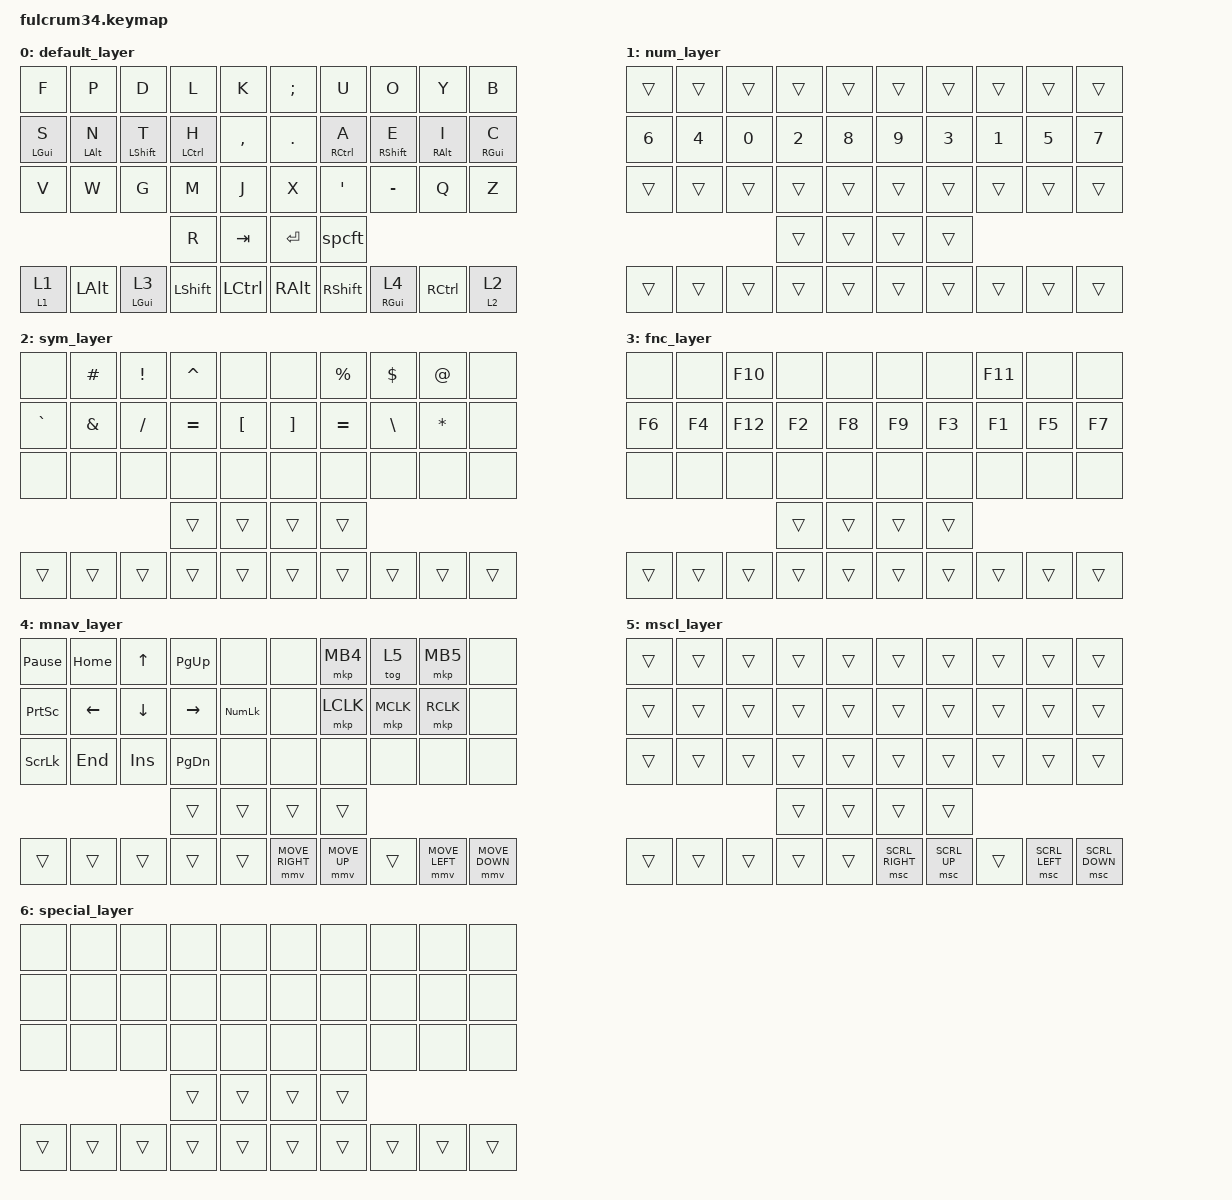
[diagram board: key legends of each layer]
/*
 * Copyright (c) 2020 The ZMK Contributors
 *
 * SPDX-License-Identifier: MIT
 */

#include <behaviors.dtsi>
#include <dt-bindings/zmk/keys.h>
#include <dt-bindings/zmk/bt.h>
#include <dt-bindings/zmk/outputs.h>
#include <dt-bindings/zmk/ext_power.h>
#include <dt-bindings/zmk/pointing.h>

#define DEFAULT 0
#define NUM 1
#define SYM 2
#define FNC 3
#define MNAV 4
#define MSCL 5
#define SPECIAL 6

/ {
    behaviors {
        hml: balanced_homerow_mods_left {
            compatible = "zmk,behavior-hold-tap";
            #binding-cells = <2>;
            tapping-term-ms = <200>;
            quick-tap-ms = <0>;
			require-prior-idle-ms = <20>;
            hold-trigger-key-positions = <5 6 7 8 9>, <15 16 17 18 19>, <25 26 27 28 29>, <30 31 32 33>, <34 35 36 37 38 39 40 41 42 43>;
			hold-trigger-on-release;
            flavor = "balanced";
            bindings = <&kp>, <&kp>;
        };
        hmr: balanced_homerow_mods_right {
            compatible = "zmk,behavior-hold-tap";
            #binding-cells = <2>;
            tapping-term-ms = <200>;
            quick-tap-ms = <0>;
			require-prior-idle-ms = <20>;
            hold-trigger-key-positions = <0 1 2 3 4>, <10 11 12 13 14>, <20 21 22 23 24>, <30 31 32 33>, <34 35 36 37 38 39 40 41 42 43>;
			hold-trigger-on-release;
            flavor = "balanced";
            bindings = <&kp>, <&kp>;
        };
		mo_tog: behavior_mo_tog {
            compatible = "zmk,behavior-hold-tap";
            #binding-cells = <2>;
            flavor = "hold-preferred";
            tapping-term-ms = <200>;
            bindings = <&mo>, <&tog>;
        };
        h_tog: behavior_hold_toggle_layer {
            compatible = "zmk,behavior-hold-tap";
            #binding-cells = <2>;
            tapping-term-ms = <200>;
            quick-tap-ms = <0>;
			require-prior-idle-ms = <20>;
            flavor = "hold-preferred";
            bindings = <&kp>, <&tog>;
        };
        h_sl: behavior_hold_sticky_layer {
            compatible = "zmk,behavior-hold-tap";
            #binding-cells = <2>;
            tapping-term-ms = <200>;
            quick-tap-ms = <0>;
			require-prior-idle-ms = <20>;
            flavor = "hold-preferred";
            bindings = <&kp>, <&sl>;
        };
		spcft: holdtap_space_faux_tab {
			compatible = "zmk,behavior-hold-tap";
			#binding-cells = <2>;
			tapping-term-ms = <200>;
			quick-tap-ms = <0>;
			require-prior-idle-ms = <20>;
			flavor = "balanced";
			bindings = <&fauxt>, <&kp SPACE>;
		};
		caps: holdtap_capsword {
			compatible = "zmk,behavior-hold-tap";
			#binding-cells = <2>;
			tapping-term-ms = <200>;
			quick-tap-ms = <0>;
			require-prior-idle-ms = <20>;
			flavor = "balanced";
			bindings = <&kp CAPS>, <&caps_word>;
		};
		caps_word: caps_word {
			compatible = "zmk,behavior-caps-word";
			#binding-cells = <0>;
			continue-list = <UNDERSCORE MINUS>;
		};
        tdbl: tap_dance_bootloader {
            compatible = "zmk,behavior-tap-dance";
            #binding-cells = <0>;
            tapping-term-ms = <200>;
            bindings = <&kp>, <&kp>, <&bootloader>;
        };
    };
	
    combos {
        compatible = "zmk,combos";
		combo_lthumb_bspc {
		    key-positions = <30 31>;
			bindings = <&kp BSPC>;
		};
		combo_rthumb_del {
		    key-positions = <32 33>;
			bindings = <&kp DEL>;
		};
		combo_ldwrdw_special_layer {
            key-positions = <34 43>;
            bindings = <&mo 6>;
        };
		combo_luprup_caps {
            key-positions = <37 40>;
            bindings = <&caps>;
        };
		combo_lfwrfw_app {
            key-positions = <38 42>;
            bindings = <&kp KP_APP>;
        };
		combo_lbkrbk_ {
            key-positions = <35 39>;
            bindings = <&kp>;
        };
		combo_linrin_ {
            key-positions = <36 41>;
            bindings = <&kp>;
        };
    };
	
	macros {
		fauxt: faux_tab {
          compatible = "zmk,behavior-macro";
          #binding-cells = <0>;
          bindings = <&macro_tap &kp SPACE &kp SPACE &kp SPACE &kp SPACE>;
      };
	};
	
        keymap {
                compatible = "zmk,keymap";
                default_layer {
// -------------------------------------------------------------------------------
// |   F  |   P  |   D  |   L  |   K  ||     ||   ;: |   U  |   O  |   Y  |   B  |
// |gui S |alt N |sft T |ctl H |   ,< |||||||||   .> |ctl A |sft E |alt I |gui C |
// |   V  |   W  |   G  |   M  |   J  ||     ||   X  |   '" |   -_ |   Q  |   Z  |
// _____________________|   R  |  tab ||     ||  ret | spcft|_____________________
// |  L1  |  alt |  gui | shft | ctrl ||     ||  alt | shft |  gui | ctrl |  L2  |
// (  DW  |  BK  |  IN  |  UP  |  FW  )       (  BK  |  UP  |  IN  |  FW  |  DW  )
                        bindings = <
   &kp F &kp P &kp D &kp L &kp K   &kp SEMI &kp U &kp O &kp Y &kp B    
   &hml LGUI S &hml LALT N &hml LSHFT T &hml LCTRL H &kp COMMA   &kp DOT &hmr RCTRL A &hmr RSHFT E &hmr RALT I &hmr RGUI C  
   &kp V &kp W &kp G &kp M &kp J   &kp X &kp QUOT &kp MINUS &kp Q &kp Z
                     &kp R &kp TAB  &kp RET &spcft
   &mo_tog 1 1 &kp LALT &h_sl LGUI 3 &kp LSHFT &kp LCTRL    &kp RALT &kp RSHFT &h_tog RGUI 4 &kp RCTRL &mo_tog 2 2
                        >;
                };
              num_layer {
// -------------------------------------------------------------------------------
// |      |      |      |      |      ||     ||      |      |      |      |      |
// |   6  |   4  |   0  |   2  |   8  |||||||||   9  |   3  |   1  |   5  |   7  |
// |      |      |      |      |      ||     ||      |      |      |      |      |
// _____________________|      |      ||     ||      |      |_____________________
// |      |      |      |      |      ||     ||      |      |      |      |      |
// (  DW  |  BK  |  IN  |  UP  |  FW  )       (  BK  |  UP  |  IN  |  FW  |  DW  )
                      bindings = <
 &trans &trans &trans &trans &trans   &trans &trans &trans &trans &trans
 &kp N6 &kp N4 &kp N0 &kp N2 &kp N8   &kp N9 &kp N3 &kp N1 &kp N5 &kp N7
 &trans &trans &trans &trans &trans   &trans &trans &trans &trans &trans
                   &trans &trans   &trans &trans
 &trans &trans &trans &trans &trans    &trans &trans &trans &trans &trans
                      >;
              };
                sym_layer {
// -------------------------------------------------------------------------------
// |      |   #  |   !  |   ^  |      ||     ||      |   %  |   $  |   @  |      |
// |  `~  |   &  |  /?  |  =+  |  [{  |||||||||  }]  |  =+  |  \|  |   *  |      |
// |      |      |      |      |      ||     ||      |      |      |      |      |
// _____________________|      |      ||     ||      |      |_____________________
// |      |      |      |      |      ||     ||      |      |      |      |      |
// (  DW  |  BK  |  IN  |  UP  |  FW  )       (  BK  |  UP  |  IN  |  FW  |  DW  )
                        bindings = <
   &none &kp HASH &kp EXCL &kp CARET &none   &none &kp PRCNT &kp DLLR &kp AT &none
   &kp GRAVE &kp AMPS &kp FSLH &kp EQUAL &kp LBKT   &kp RBKT &kp EQUAL &kp BSLH &kp ASTRK &none
   &none &none &none &none &none   &none &none &none &none &none
                     &trans &trans   &trans &trans
   &trans &trans &trans &trans &trans    &trans &trans &trans &trans &trans 
                        >;
                };
//              sym_layer { // BAK
// -------------------------------------------------------------------------------
// |   ~  |   @  |   <  |   {  |   [  ||     ||   ]  |   }  |   >  |   @  |   ~  |
// |   ^  |   +  |   *  |   &  |   =  |||||||||   =  |   &  |   *  |   +  |   ^  |
// |   `  |   %  |   $  |   |  |   #  ||     ||   #  |   |  |   $  |   %  |   `  |
// _____________________|      |      ||     ||      |      |_____________________
// |      |      |      |      |      ||     ||      |      |      |      |      |
// (  DW  |  BK  |  IN  |  UP  |  FW  )       (  BK  |  UP  |  IN  |  FW  |  DW  )
//                      bindings = <
// &kp TILDE &kp AT &kp LT &kp LBRC &kp LBKT   &kp RBKT &kp RBRC &kp GT &kp AT &kp TILDE
// &kp CARET &kp PLUS &kp STAR &kp AMPS &kp EQUAL   &kp EQUAL &kp AMPS &kp STAR &kp PLUS &kp CARET
// &kp GRAVE &kp PRCNT &kp DLLR &kp PIPE &kp HASH   &kp HASH &kp PIPE &kp DLLR &kp PRCNT &kp GRAVE
//                   &trans &trans   &trans &trans
// &trans &trans &trans &trans &trans    &trans &trans &trans &trans &trans
//                      >;
//              };
                fnc_layer {
// -------------------------------------------------------------------------------
// |      |      |  F10 |      |      ||     ||      |      |  F11 |      |      |
// |  F6  |  F4  |  F12 |  F2  |  F8  |||||||||  F9  |  F3  |  F1  |  F5  |  F7  |
// |      |      |      |      |      ||     ||      |      |      |      |      |
// _____________________|      |      ||     ||      |      |_____________________
// |      |      |      |      |      ||     ||      |      |      |      |      |
// (  DW  |  BK  |  IN  |  UP  |  FW  )       (  BK  |  UP  |  IN  |  FW  |  DW  )
                        bindings = <
   &none &none &kp F10 &none &none   &none &none &kp F11 &none &none
   &kp F6 &kp F4 &kp F12 &kp F2 &kp F8   &kp F9 &kp F3 &kp F1 &kp F5 &kp F7
   &none &none &none &none &none   &none &none &none &none &none
                     &trans &trans   &trans &trans
   &trans &trans &trans &trans &trans    &trans &trans &trans &trans &trans
                        >;
                };
                mnav_layer {
// -------------------------------------------------------------------------------
// | PSBR | HOME |  UP  | PGUP |      ||     ||      |  MB4 |  L5  |  MB5 |      |
// | PSCR |  LT  |  DN  |  RT  | NMLK |||||||||      | LCLK | MCLK | RCLK |      |
// | SLCK |  END |  INS | PGDN | NMLK ||     ||      |      |      |      |      |
// _____________________|      |      ||     ||      |      |_____________________
// |      |      |      |      |      ||     || MMVR | MMVU |      | MMVL | MMVD |
// (  DW  |  BK  |  IN  |  UP  |  FW  )       (  BK  |  UP  |  IN  |  FW  |  DW  )
                        bindings = <
   &kp PAUSE_BREAK &kp HOME &kp UP &kp PG_UP &none      &none &mkp MB4 &tog 5 &mkp MB5 &none
   &kp PSCRN &kp LEFT &kp DOWN &kp RIGHT &kp KP_NUM      &none &mkp LCLK &mkp MCLK &mkp RCLK &none
   &kp SLCK &kp END &kp INS &kp PG_DN &none       &none &none &none &none &none
                     &trans &trans   &trans &trans
   &trans &trans &trans &trans &trans    &mmv MOVE_RIGHT &mmv MOVE_UP &trans &mmv MOVE_LEFT &mmv MOVE_DOWN
                        >;
                };
                mscl_layer {
// -------------------------------------------------------------------------------
// |      |      |      |      |      ||     ||      |      |      |      |      |
// |      |      |      |      |      |||||||||      |      |      |      |      |
// |      |      |      |      |      ||     ||      |      |      |      |      |
// _____________________|      |      ||     ||      |      |_____________________
// |      |      |      |      |      ||     || MSCR | MSCU |      | MSCL | MSCD |
// (  DW  |  BK  |  IN  |  UP  |  FW  )       (  BK  |  UP  |  IN  |  FW  |  DW  )
                        bindings = <
   &trans &trans &trans &trans &trans   &trans &trans &trans &trans &trans
   &trans &trans &trans &trans &trans   &trans &trans &trans &trans &trans
   &trans &trans &trans &trans &trans   &trans &trans &trans &trans &trans
                     &trans &trans   &trans &trans
   &trans &trans &trans &trans &trans    &msc SCRL_RIGHT &msc SCRL_UP &trans &msc SCRL_LEFT &msc SCRL_DOWN 
                        >;
                };
                special_layer {
// -------------------------------------------------------------------------------
// |      |      |      |      |      ||     ||      |      |      |      |      |
// |      |      |      |      |      |||||||||      |      |      |      |      |
// |      |      |      |      |      ||     ||      |      |      |      |      |
// _____________________|      |      ||     ||      |      |_____________________
// |      |      |      |      |      ||     ||      |      |      |      |      |
// (  DW  |  BK  |  IN  |  UP  |  FW  )       (  BK  |  UP  |  IN  |  FW  |  DW  )
                        bindings = <
   &none &none &none &none &none   &none &none &none &none &none
   &none &none &none &none &none   &none &none &none &none &none
   &none &none &none &none &none   &none &none &none &none &none
                     &trans &trans   &trans &trans
   &trans &trans &trans &trans &trans    &trans &trans &trans &trans &trans 
                        >;
                };
        };
};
